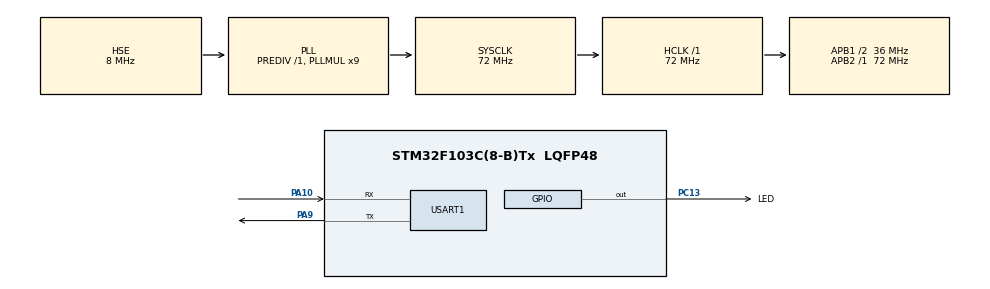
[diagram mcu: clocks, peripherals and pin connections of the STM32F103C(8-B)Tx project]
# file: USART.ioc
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Mcu.Family=STM32F1
Mcu.Name=STM32F103C(8-B)Tx
Mcu.Package=LQFP48
NVIC.PriorityGroup=NVIC_PRIORITYGROUP_4
NVIC.USART1_IRQn=true\:0\:0\:false\:false\:true\:true\:true
PA10.Mode=Asynchronous
PA10.Signal=USART1_RX
PA13.Mode=Serial_Wire
PA13.Signal=SYS_JTMS-SWDIO
PA14.Mode=Serial_Wire
PA14.Signal=SYS_JTCK-SWCLK
PA9.Mode=Asynchronous
PA9.Signal=USART1_TX
PC13-TAMPER-RTC.GPIO_Label=LED
PC13-TAMPER-RTC.Signal=GPIO_Output
PD0-OSC_IN.Mode=HSE-External-Oscillator
PD0-OSC_IN.Signal=RCC_OSC_IN
PD1-OSC_OUT.Mode=HSE-External-Oscillator
PD1-OSC_OUT.Signal=RCC_OSC_OUT
ProjectManager.HeapSize=0x200
ProjectManager.StackSize=0x400
ProjectManager.TargetToolchain=STM32CubeIDE
RCC.AHBFreq_Value=72000000
RCC.APB1CLKDivider=RCC_HCLK_DIV2
RCC.APB1Freq_Value=36000000
RCC.APB1TimFreq_Value=72000000
RCC.APB2Freq_Value=72000000
RCC.APB2TimFreq_Value=72000000
RCC.HCLKFreq_Value=72000000
RCC.PLLMUL=RCC_PLL_MUL9
RCC.PLLSourceVirtual=RCC_PLLSOURCE_HSE
RCC.SYSCLKFreq_VALUE=72000000
RCC.SYSCLKSource=RCC_SYSCLKSOURCE_PLLCLK
RCC.USBFreq_Value=72000000
USART1.VirtualMode=VM_ASYNC
board=custom

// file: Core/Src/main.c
/* USER CODE BEGIN Header */
/**
  ******************************************************************************
  * @file           : main.c
  * @brief          : Main program body
  ******************************************************************************
  * @attention
  *
  * Copyright (c) 2022 STMicroelectronics.
  * All rights reserved.
  *
  * This software is licensed under terms that can be found in the LICENSE file
  * in the root directory of this software component.
  * If no LICENSE file comes with this software, it is provided AS-IS.
  *
  ******************************************************************************
  */
/* USER CODE END Header */
#include "main.h"
#include "usart.h"
#include "gpio.h"

/* USER CODE BEGIN Includes */
#include "retarget.h"
#include <string.h>

/* USER CODE END Includes */

/* USER CODE BEGIN PD */
#define RXBUFFERSIZE  256     //最大接收字节数

/* USER CODE END PD */

/* USER CODE BEGIN PV */
char RxBuffer[RXBUFFERSIZE];   //接收数据
uint8_t aRxBuffer;            //接收中断缓冲
uint8_t Uart1_Rx_Cnt = 0;        //接收缓冲计数
/* USER CODE END PV */

void SystemClock_Config(void);

int main(void) {

    /* MCU Configuration--------------------------------------------------------*/

    /* Reset of all peripherals, Initializes the Flash interface and the Systick. */
    HAL_Init();

    /* Configure the system clock */
    SystemClock_Config();

    /* Initialize all configured peripherals */
    MX_GPIO_Init();
    MX_USART1_UART_Init();
    /* USER CODE BEGIN 2 */
    //
    RetargetInit(&huart1);
    /* USER CODE END 2 */

    /* Infinite loop */
    /* USER CODE BEGIN WHILE */
    printf("欢迎来到洛尘的CSDN");
    HAL_UART_Receive_IT(&huart1, (uint8_t *) &aRxBuffer, 1);
    while (1) {
        /* USER CODE END WHILE */

    }
}

void SystemClock_Config(void) {
    RCC_OscInitTypeDef RCC_OscInitStruct = {0};
    RCC_ClkInitTypeDef RCC_ClkInitStruct = {0};

    /** Initializes the RCC Oscillators according to the specified parameters
    * in the RCC_OscInitTypeDef structure.
    */
    RCC_OscInitStruct.OscillatorType = RCC_OSCILLATORTYPE_HSE;
    RCC_OscInitStruct.HSEState = RCC_HSE_ON;
    RCC_OscInitStruct.HSEPredivValue = RCC_HSE_PREDIV_DIV1;
    RCC_OscInitStruct.HSIState = RCC_HSI_ON;
    RCC_OscInitStruct.PLL.PLLState = RCC_PLL_ON;
    RCC_OscInitStruct.PLL.PLLSource = RCC_PLLSOURCE_HSE;
    RCC_OscInitStruct.PLL.PLLMUL = RCC_PLL_MUL9;
    if (HAL_RCC_OscConfig(&RCC_OscInitStruct) != HAL_OK) {
        Error_Handler();
    }
    /** Initializes the CPU, AHB and APB buses clocks
    */
    RCC_ClkInitStruct.ClockType = RCC_CLOCKTYPE_HCLK | RCC_CLOCKTYPE_SYSCLK
                                  | RCC_CLOCKTYPE_PCLK1 | RCC_CLOCKTYPE_PCLK2;
    RCC_ClkInitStruct.SYSCLKSource = RCC_SYSCLKSOURCE_PLLCLK;
    RCC_ClkInitStruct.AHBCLKDivider = RCC_SYSCLK_DIV1;
    RCC_ClkInitStruct.APB1CLKDivider = RCC_HCLK_DIV2;
    RCC_ClkInitStruct.APB2CLKDivider = RCC_HCLK_DIV1;

    if (HAL_RCC_ClockConfig(&RCC_ClkInitStruct, FLASH_LATENCY_2) != HAL_OK) {
        Error_Handler();
    }
}

/* USER CODE BEGIN 4 */
void HAL_UART_RxCpltCallback(UART_HandleTypeDef *huart) {
    /* Prevent unused argument(s) compilation warning */
    UNUSED(huart);
    /* NOTE: This function Should not be modified, when the callback is needed,
             the HAL_UART_TxCpltCallback could be implemented in the user file
     */

    if (Uart1_Rx_Cnt >= 255)  //溢出判断
    {
        Uart1_Rx_Cnt = 0;
        memset(RxBuffer, 0x00, sizeof(RxBuffer));
        HAL_UART_Transmit(&huart1, (uint8_t *) "数据溢出", 10, 0xFFFF);
    } else {
        RxBuffer[Uart1_Rx_Cnt++] = aRxBuffer;   //接收数据转存

        if ((RxBuffer[Uart1_Rx_Cnt - 1] == 0x0A) && (RxBuffer[Uart1_Rx_Cnt - 2] == 0x0D)) //判断结束位
        {
            HAL_UART_Transmit(&huart1, (uint8_t *) &RxBuffer, Uart1_Rx_Cnt, 0xFFFF); //将收到的信息发送出去
            while (HAL_UART_GetState(&huart1) == HAL_UART_STATE_BUSY_TX);//检测UART发送结束
            if (strstr(RxBuffer, "LED=0")) {
                HAL_GPIO_WritePin(LED_GPIO_Port, LED_Pin, 0); //PC口13引脚输出，高电平
                printf("LED亮\r\n");
            } else if (strstr(RxBuffer, "LED=1")) {
                HAL_GPIO_WritePin(LED_GPIO_Port, LED_Pin, 1); //PC口13引脚输出，低电平
                printf("LED灭\r\n");
            }
            Uart1_Rx_Cnt = 0;
            memset(RxBuffer, 0x00, sizeof(RxBuffer)); //清空数组
        }
    }
    HAL_UART_Receive_IT(&huart1, (uint8_t *) &aRxBuffer, 1);   //再开启接收中断
}
/* USER CODE END 4 */

void Error_Handler(void) {
    __disable_irq();
    while (1) {
    }
}
